# SF32LB55x register map
File version: 1.0
CPU: CM33 r0p1, little endian, MPU, FPU, 3 interrupt priority bits
Registers are 32-bit, read-write, reset 0x0 unless marked. A register's access mark holds for its fields unless they carry their own. Offsets are from the block's base; [hi:lo] are bit positions; {n}, {i} and the like mark numbered series.

## LPSYS_AON
Base 0x40070000
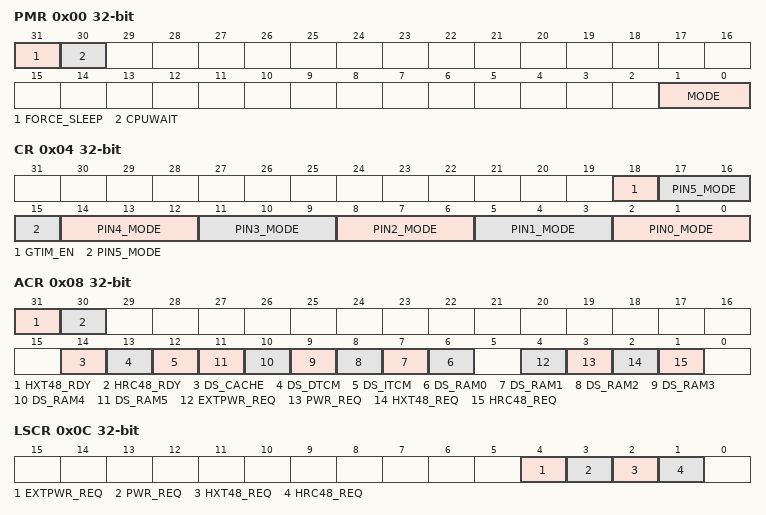
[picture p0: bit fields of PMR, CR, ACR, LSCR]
0x00 PMR — Power Mode Register
  [31] FORCE_SLEEP — force to enter low power mode (for debug only)
  [30] CPUWAIT — Stall CPU out of reset. Should be cleared before LCPU run
  [1:0] MODE — Power Mode: 2'h0 - active/idle; 2'h1 - light sleep; 2'h2 - deep sleep; 2'h3 - standby
0x04 CR — Control Register
  [18] GTIM_EN — Enable global timer
  [3n+2:3n] PIN{n}_MODE (n=1..5) — mode for wakeup PIN{n} (PB{n+43})
  [2:0] PIN0_MODE — mode for wakeup PIN0 (PB43) 0 - high level, 1 - low level, 2 - pos edge, 3 - neg edge, 4/5/6/7: pos or neg edge
0x08 ACR — Active Mode Control register
  [31] HXT48_RDY — Indicate hxt48 is ready
  [30] HRC48_RDY — Indicate hrc48 is ready
  [14] DS_CACHE — for debug only
  [13] DS_DTCM — for debug only
  [12] DS_ITCM — for debug only
  [n+6] DS_RAM{n} (n=0..5) — for debug only
  [4] EXTPWR_REQ — Request power for HPSYS during Active mode
  [3] PWR_REQ — Request power for LPSYS during Active mode
  [2] HXT48_REQ — Request hxt48 in active mode
  [1] HRC48_REQ — Request hrc48 in active mode
0x0C LSCR — Light Sleep Ctrl Register
  [4] EXTPWR_REQ — Request power for HPSYS during Light Sleep mode
  [3] PWR_REQ — Request power for LPSYS during Light Sleep mode
  [2] HXT48_REQ — Request hxt48 in Light Sleep mode
  [1] HRC48_REQ — Request hrc48 in Light Sleep mode
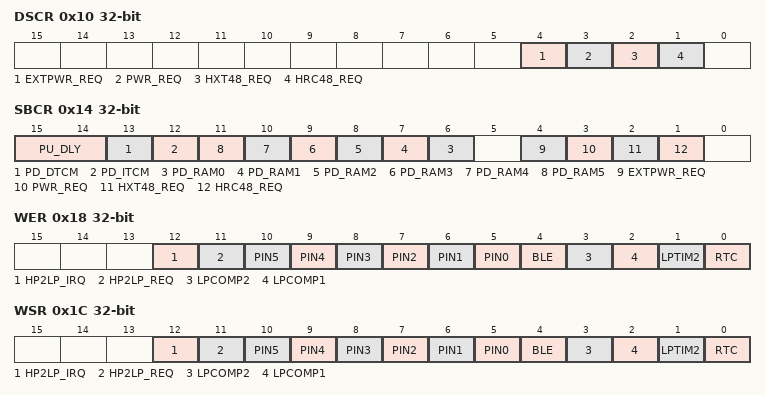
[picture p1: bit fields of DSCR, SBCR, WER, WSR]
0x10 DSCR — Deep Sleep Ctrl Register
  [4] EXTPWR_REQ — Request power for HPSYS during Deep Sleep mode
  [3] PWR_REQ — Request power for LPSYS during Deep Sleep mode
  [2] HXT48_REQ — Request hxt48 in Deep Sleep mode
  [1] HRC48_REQ — Request hrc48 in Deep Sleep mode
0x14 SBCR — Standby Mode Ctrl Register
  [15:14] PU_DLY — for debug only
  [13] PD_DTCM — for debug only
  [12] PD_ITCM — for debug only
  [n+6] PD_RAM{n} (n=0..5) — for debug only
  [4] EXTPWR_REQ — Request power for HPSYS during Standby mode
  [3] PWR_REQ — Request power for LPSYS during Standby mode
  [2] HXT48_REQ — Request hxt48 in Standby mode
  [1] HRC48_REQ — Request hrc48 in Standby mode
0x18 WER — Wakeup Enable register
  [12] HP2LP_IRQ — Set 1 to enable MAILBOX1 as wakeup source
  [11] HP2LP_REQ — Set 1 to enable HPSYS request as wakeup source
  [n+5] PIN{n} (n=0..5) — Set 1 to enable PB{n+43} as wakeup source
  [4] BLE — Set 1 to enable BLE as wakeup source
  [3] LPCOMP2 — Set 1 to enable LPCOMP2 as wakeup source
  [2] LPCOMP1 — Set 1 to enable LPCOMP1 as wakeup source
  [1] LPTIM2 — Set 1 to enable LPTIM2 as wakeup source
  [0] RTC — Set 1 to enable RTC as wakeup source
0x1C WSR — Wakeup Status register
  [12] HP2LP_IRQ — Indicates the wakeup status from MAILBOX1. Note: the status is masked by WER
  [11] HP2LP_REQ — Indicates the wakeup status from HPSYS request. Note: the status is masked by WER
  [n+5] PIN{n} (n=0..5) — Indicates the wakeup status from PB{n+43} request. Note: the status is masked by WER
  [4] BLE — Indicates the wakeup status from BLE. Note: the status is masked by WER
  [3] LPCOMP2 — Indicates the wakeup status from LPCOMP2. Note: the status is masked by WER
  [2] LPCOMP1 — Indicates the wakeup status from LPCOMP1. Note: the status is masked by WER
  [1] LPTIM2 — Indicates the wakeup status from LPTIM2. Note: the status is masked by WER
  [0] RTC — Indicates the wakeup status from RTC. Note: the status is masked by WER
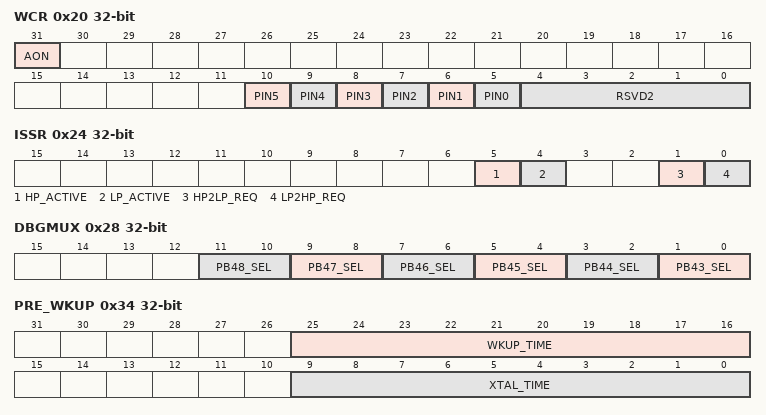
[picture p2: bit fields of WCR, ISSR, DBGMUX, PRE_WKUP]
0x20 WCR — Wakeup Clear register
  [31] AON — Write 1 to clear the AON wakeup IRQ status
  [n+5] PIN{n} (n=0..5) — Write 1 to clear the PB{n+43} wakeup source. Only valid if PIN wakeup is configured as edge trigger
  [4:0] RSVD2 — Note: for RTC/LPTIM/LPCOMP/BLE, clear the wakeup status directly in the corresponding module
0x24 ISSR — Inter System Status Register
  [5] HP_ACTIVE — read 1 indicates HPSYS is active
  [4] LP_ACTIVE — write 1 to indicates LPSYS is active
  [1] HP2LP_REQ — indicate HPSYS request exists
  [0] LP2HP_REQ — write 1 to request HPSYS to stay in active mode
0x28 DBGMUX — Debug Mux Register
  [2n-85:2n-86] PB{n}_SEL (n=43..48) — for debug only
0x2C TARGET — BLE sleep time target
  [27:0] SLEEP_TARGET — ble sleep time target in cycles of clk_lp
0x30 ACTUAL — BLE actual sleep time
  [27:0] SLEEP_CNT — ble actual sleep time in cycles of clk_lp. If not woken up by software or external interrupt, sleep_cnt counts up every low power clock cycle, until reaches sleep_target
0x34 PRE_WKUP — time before ble awake
  [25:16] WKUP_TIME — cycles of clk_lp for LPSYS ready before bt awake.
  [9:0] XTAL_TIME — cycles of clk_lp for hxt48 ready before bt awake.
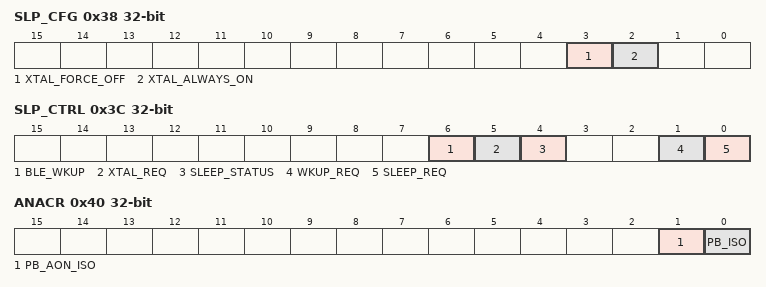
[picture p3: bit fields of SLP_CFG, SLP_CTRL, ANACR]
0x38 SLP_CFG — ble sleep configuration
  [3] XTAL_FORCE_OFF — for debug only
  [2] XTAL_ALWAYS_ON — for debug only
0x3C SLP_CTRL — ble sleep control
  [6] BLE_WKUP — ble wakeup source. 1 means ble has not enter sleep or has enter wakeup procedure
  [5] XTAL_REQ — xtal request status. 1 means ble is requiring xtal.
  [4] SLEEP_STATUS — ble sleep status. 1 means ble is sleeping and sleep_cnt is counting up
  [1] WKUP_REQ — software request to wakeup ble. Will be cleared automatically
  [0] SLEEP_REQ — ble sleep request. Will be cleared automatically
0x40 ANACR — Analog Control Register
  [1] PB_AON_ISO — Set 1 to force off all LPSYS related analog modules
  [0] PB_ISO — Set 1 to force IO(PB) into retention mode
0x44 GTIMR — Global Timer Register
  [31:0] CNT — Global timer value
0x48 RESERVE0 — Reserved Register 0
  [31:0] DATA — for debug only
0x4C RESERVE1 — Reserved Register 1
  [31:0] DATA — for debug only
0x100 SPR — Stack Pointer Register
  [31:0] SP — LCPU stack pointer address
0x104 PCR — Pointer Counter Register
  [31:0] PC — LCPU PC pointer address
